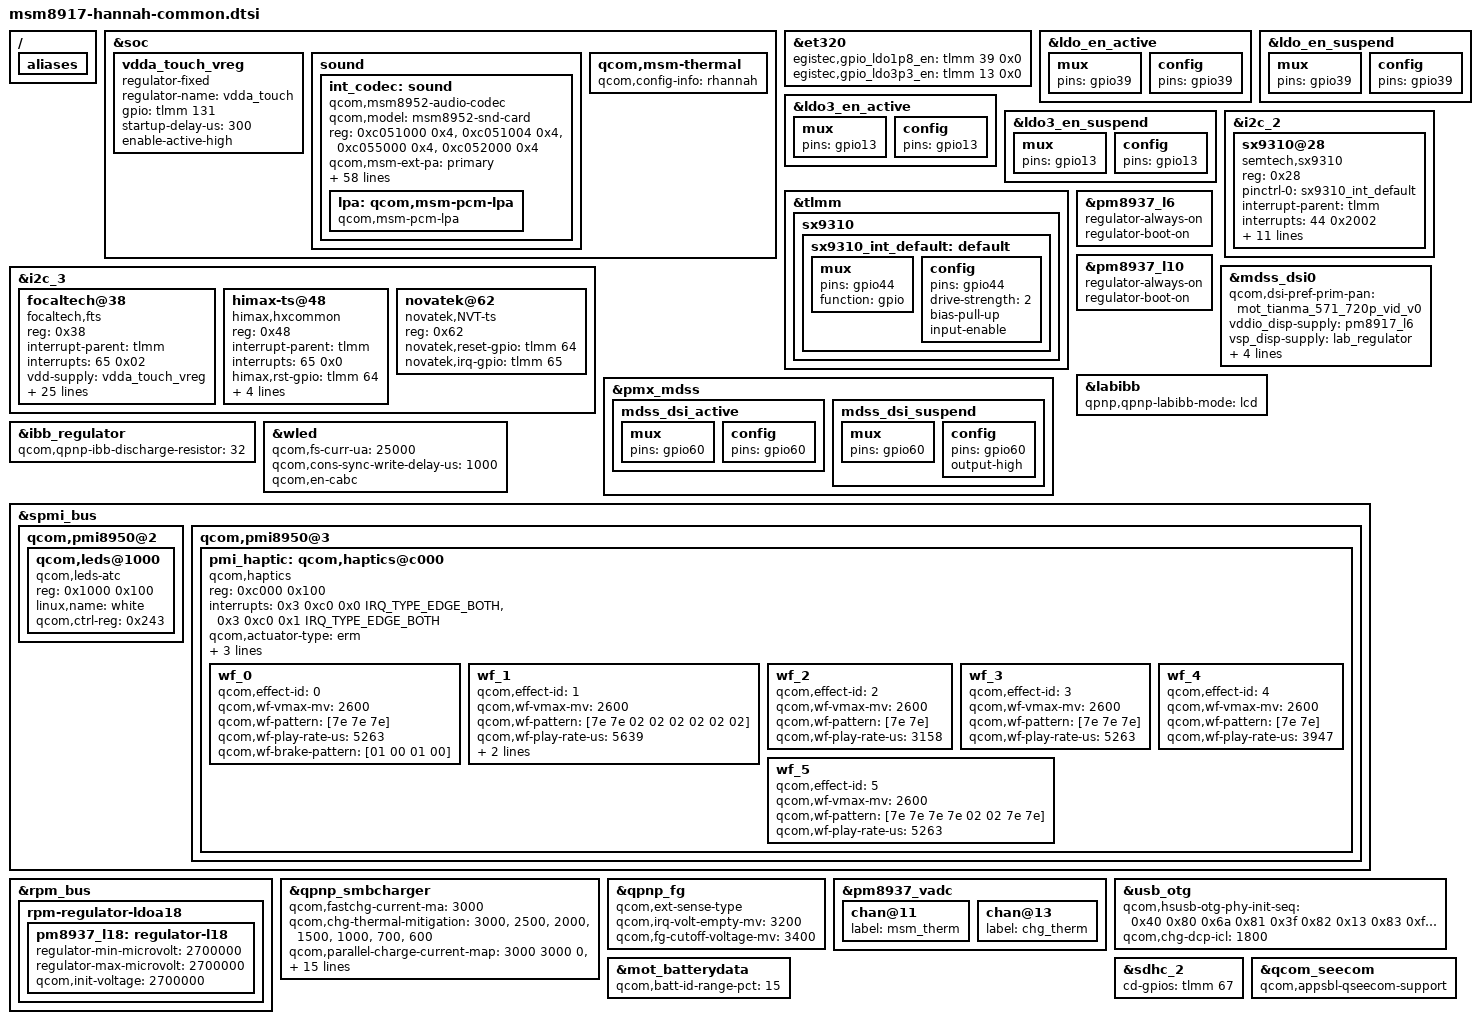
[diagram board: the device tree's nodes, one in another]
/* Copyright (c) 2016, Motorola Mobility Inc. All rights reserved.
 *
 * This program is free software; you can redistribute it and/or modify
 * it under the terms of the GNU General Public License version 2 and
 * only version 2 as published by the Free Software Foundation.
 *
 * This program is distributed in the hope that it will be useful,
 * but WITHOUT ANY WARRANTY; without even the implied warranty of
 * MERCHANTABILITY or FITNESS FOR A PARTICULAR PURPOSE.  See the
 * GNU General Public License for more details.
 */
#include "dsi-panel-mot-tianma-571-720p-video.dtsi"
#include "dsi-panel-mot-djn-599-hd-video.dtsi"
#include "dsi-panel-mot-tianma-599-hd-video.dtsi"
#include "dsi-panel-mot-djn-600-hd-video.dtsi"
#include "msm8917-moto-common-fps.dtsi"

/ {
	aliases {
		/delete-property/ i2c4;
	};
};

&soc {
	/delete-node/ i2c@78b8000;

	vdda_touch_vreg: vdda_touch_vreg {
		compatible = "regulator-fixed";
		regulator-name = "vdda_touch";
		gpio = <&tlmm 131 0>;
		startup-delay-us = <300>;
		enable-active-high;
	};

	sound {
		int_codec: sound {
		    status = "okay";
		    compatible = "qcom,msm8952-audio-codec";
		    qcom,model = "msm8952-snd-card";
		    reg = <0xc051000 0x4>,
		      <0xc051004 0x4>,
		      <0xc055000 0x4>,
		      <0xc052000 0x4>;
		    reg-names = "csr_gp_io_mux_mic_ctl",
		      "csr_gp_io_mux_spkr_ctl",
		      "csr_gp_io_lpaif_pri_pcm_pri_mode_muxsel",
		      "csr_gp_io_mux_quin_ctl";

		    qcom,msm-ext-pa = "primary";
		    qcom,msm-mclk-freq = <9600000>;
		    qcom,msm-mbhc-hphl-swh = <1>;
		    qcom,msm-mbhc-gnd-swh = <1>;
		    qcom,msm-hs-micbias-type = "external";
		    qcom,msm-hs-insert-debounce = <9>;
		    /delete-property/ qcom,msm-micbias2-ext-cap;
		    qcom,msm-micbias1-ext-cap;

		    qcom,audio-routing =
		      "RX_BIAS", "MCLK",
		      "INT_LDO_H", "MCLK",
		      "MIC BIAS External", "Handset Mic",
		      "MIC BIAS External2", "Headset Mic",
		      "MIC BIAS External", "Secondary Mic",
		      "AMIC1", "MIC BIAS External",
		      "AMIC2", "MIC BIAS External2",
		      "AMIC3", "MIC BIAS External";

		    qcom,cdc-us-eu-gpios = <&cdc_us_euro_sw>;
		    qcom,pri-mi2s-gpios = <&cdc_pri_mi2s_gpios>;
		    qcom,quin-mi2s-gpios = <&cdc_quin_mi2s_gpios>;

		    asoc-platform = <&pcm0>, <&pcm1>, <&pcm2>, <&voip>, <&voice>,
		        <&loopback>, <&compress>, <&hostless>,
		        <&afe>, <&lsm>, <&routing>, <&pcm_noirq>;
		    asoc-platform-names = "msm-pcm-dsp.0", "msm-pcm-dsp.1",
		        "msm-pcm-dsp.2", "msm-voip-dsp",
		        "msm-pcm-voice", "msm-pcm-loopback",
		        "msm-compress-dsp", "msm-pcm-hostless",
		        "msm-pcm-afe", "msm-lsm-client",
		        "msm-pcm-routing", "msm-pcm-dsp-noirq";
		    asoc-cpu = <&dai_pri_auxpcm>,
		      <&dai_mi2s0>, <&dai_mi2s1>,
		      <&dai_mi2s2>, <&dai_mi2s3>,
		      <&dai_mi2s4>, <&dai_mi2s5>,
		      <&sb_0_rx>, <&sb_0_tx>, <&sb_1_rx>, <&sb_1_tx>,
		      <&sb_3_rx>, <&sb_3_tx>, <&sb_4_rx>, <&sb_4_tx>,
		      <&bt_sco_rx>, <&bt_sco_tx>,
		      <&int_fm_rx>, <&int_fm_tx>,
		      <&afe_pcm_rx>, <&afe_pcm_tx>,
		      <&afe_proxy_rx>, <&afe_proxy_tx>,
		      <&incall_record_rx>, <&incall_record_tx>,
		      <&incall_music_rx>, <&incall_music_2_rx>,
		      <&proxy_rx>, <&proxy_tx>;

		    asoc-cpu-names = "msm-dai-q6-auxpcm.1",
		        "msm-dai-q6-mi2s.0", "msm-dai-q6-mi2s.1",
		        "msm-dai-q6-mi2s.2", "msm-dai-q6-mi2s.3",
		        "msm-dai-q6-mi2s.4", "msm-dai-q6-mi2s.6",
		        "msm-dai-q6-dev.16384", "msmdai-q6-dev.16385",
		        "msm-dai-q6-dev.16386", "msm-dai-q6-dev.16387",
		        "msm-dai-q6-dev.16390", "msm-dai-q6-dev.16391",
		        "msm-dai-q6-dev.16392", "msm-dai-q6-dev.16393",
		        "msm-dai-q6-dev.12288", "msm-dai-q6-dev.12289",
		        "msm-dai-q6-dev.12292", "msm-dai-q6-dev.12293",
		        "msm-dai-q6-dev.224", "msm-dai-q6-dev.225",
		        "msm-dai-q6-dev.241", "msm-dai-q6-dev.240",
		        "msm-dai-q6-dev.32771", "msm-dai-q6-dev.32772",
		        "msm-dai-q6-dev.32773", "msm-dai-q6-dev.32770",
		        "msm-dai-q6-dev.8194", "msm-dai-q6-dev.8195";

		    asoc-codec = <&stub_codec>, <&msm_digital_codec>,
		        <&pmic_analog_codec>;
		    asoc-codec-names = "msm-stub-codec.1", "msm-dig-codec",
		          "analog-codec";
    
		    qcom,msm-gpios =
		      "pri_i2s";
		    qcom,pinctrl-names =
		      "all_off",
		      "pri_i2s_act";
		    pinctrl-names =
		      "all_off",
		      "pri_i2s_act";
		    pinctrl-0 = <&cdc_pdm_lines_sus &cdc_pdm_lines_2_sus>;
		    pinctrl-1 = <&cdc_pdm_lines_act &cdc_pdm_lines_2_act>;
		    /delete-property/ pinctrl-2;
		    /delete-property/ pinctrl-3;
		    /delete-property/ pinctrl-4;
		    /delete-property/ pinctrl-5;
		    /delete-property/ pinctrl-6;
		    /delete-property/ pinctrl-7;
		    /delete-property/ asoc-wsa-codec-names;
		    /delete-property/ asoc-wsa-codec-prefixes;
		    /delete-property/ msm-vdd-wsa-switch-supply;
		    /delete-property/ qcom,msm-vdd-wsa-switch-voltage;
		    /delete-property/ qcom,msm-vdd-wsa-switch-current;
		    /delete-property/ qcom,hdmi-dba-codec-rx;
		    /delete-property/ qcom,cdc-us-euro-gpios;

			  lpa: qcom,msm-pcm-lpa {
			    compatible = "qcom,msm-pcm-lpa";
			  };
		  };
	};

	/delete-node/ fp_id;
};

&et320 {
	egistec,gpio_ldo1p8_en = <&tlmm 39 0x0>;
	egistec,gpio_ldo3p3_en = <&tlmm 13 0x0>;
};

&ldo_en_active {
	mux {
		pins = "gpio39";
	};
	config {
		pins = "gpio39";
	};
};

&ldo_en_suspend {
	mux {
		pins = "gpio39";
	};
	config {
		pins = "gpio39";
	};
};

&ldo3_en_active {
	mux {
		pins = "gpio13";
	};
	config {
		pins = "gpio13";
	};
};

&ldo3_en_suspend {
	mux {
		pins = "gpio13";
	};
	config {
		pins = "gpio13";
	};
};

&tlmm{
	/delete-node/ sx9310;
	sx9310:sx9310 {
		sx9310_int_default: default {
			mux {
				pins = "gpio44";
				function = "gpio";
			};

			config {
				pins = "gpio44";
				drive-strength = <2>;
				bias-pull-up;
				input-enable;
			};
		};
	};
};

&i2c_2 {
	sx9310@28 {
		compatible = "semtech,sx9310";
		reg = <0x28>;
		pinctrl-names = "default";
		pinctrl-0 = <&sx9310_int_default>;
		interrupt-parent = <&tlmm>;
		interrupts = <44 0x2002>;
		cap_vdd-supply = <&pm8917_l10>;
		cap_svdd-supply = <&pm8937_l5>;
		gpios = <&tlmm 44 0x2008>; /* IRQ */
		cap,use_channel = <0x0f>;
		cap,use_channel_top = <0x00>;
		cap,use_channel_bottom = <0x02>;
		cap,raw_data_channel = <0x01>;
		cap,scan_period = <0x02>;
		reg_array_len = <10>;
		reg_array_val = <0x12 0x03 0x13 0x0a 0x14 0x27 0x15 0xc3 0x17 0x4b 0x18 0x49 0x19 0x39 0x21 0x1a 0x22 0x05 0x23 0x20>;
	};

	/delete-node/ adv7533@39;
	/delete-node/ pericom-type-c@1d;
};


&i2c_3 {
	status = "ok";
	/* clock-frequency = <400000>; */
	focaltech@38{
		compatible = "focaltech,fts";
		reg = <0x38>;
		interrupt-parent = <&tlmm>;
		interrupts = <65 0x02>;
		/* vdd-supply = <&pm8917_l17>; */
		vdd-supply = <&vdda_touch_vreg>;
		vcc_i2c-supply = <&pm8917_l6>;
		/* pins used by touchscreen */
		pinctrl-names = "pmx_ts_active","pmx_ts_suspend","pmx_ts_release";
		pinctrl-0 = <&ts_int_active &ts_reset_active>;
		pinctrl-1 = <&ts_int_suspend &ts_reset_suspend>;
		pinctrl-2 = <&ts_release>;
		focaltech,name = "fts_ts";
		focaltech,family-id = <0x08>;
		focaltech,reset-gpio = <&tlmm 64 0x01>;
		focaltech,irq-gpio = <&tlmm 65 0x02>;
		focaltech,display-coords = <0 0 720 1440>;
		focaltech,max-touch-number = <10>;
		focaltech,no-force-update;
		focaltech,i2c-pull-up;
		focaltech,group-id = <1>;
		focaltech,hard-reset-delay-ms = <20>;
		focaltech,soft-reset-delay-ms = <200>;
		focaltech,num-max-touches = <5>;
		focaltech,fw-delay-aa-ms = <30>;
		focaltech,fw-delay-55-ms = <30>;
		focaltech,fw-upgrade-id1 = <0x79>;
		focaltech,fw-upgrade-id2 = <0x08>;
		focaltech,fw-delay-readid-ms = <10>;
		focaltech,fw-delay-era-flsh-ms = <2000>;
		focaltech,fw-auto-cal;
		focaltech,resume-in-workqueue;
		focaltech,ignore-id-check;
	};
	himax-ts@48 {
		compatible = "himax,hxcommon";
		reg = <0x48>;
		status = "ok";
		interrupt-parent = <&tlmm>;
		interrupts = <65 0x0>;
		//vcc_i2c-supply = <&pm8917_l6>;
		/* pins used by touchscreen */
		himax,rst-gpio = <&tlmm 64 0x00>;
		himax,irq-gpio = <&tlmm 65 0x00>;
		himax,display-coords = <0 720 0 1440>;
		himax,panel-coords = <0 720 0 1440>;
		//himax,button-map = <158 102 139>;
		//himax,fw-auto-update;
		/*himax,force-update;*/
		report_type = <1>;
	};
	novatek@62 {
		compatible = "novatek,NVT-ts";
		reg = <0x62>;
		status = "ok";

		novatek,reset-gpio = <&tlmm 64 0x00>;
		novatek,irq-gpio = <&tlmm 65 0x00>;
	};

};

&pmx_mdss {
	mdss_dsi_active {
		mux {
			pins = "gpio60";
		};

		config {
			pins = "gpio60";
		};
	};

	mdss_dsi_suspend {
		mux {
			pins = "gpio60";
		};

		config {
			pins = "gpio60";
			output-high;
		};
	};
};

&pm8937_l6 {
	regulator-always-on;
	regulator-boot-on;
};

&pm8937_l10 {
	regulator-always-on;
	regulator-boot-on;
};

&mdss_dsi0 {
	qcom,dsi-pref-prim-pan = <&mot_tianma_571_720p_vid_v0>;
	vddio_disp-supply = <&pm8917_l6>;
	vsp_disp-supply = <&lab_regulator>;
	vsn_disp-supply = <&ibb_regulator>;

	pinctrl-names = "mdss_default", "mdss_sleep";
	pinctrl-0 = <&mdss_dsi_active>;
	pinctrl-1 = <&mdss_dsi_suspend>;

	qcom,platform-reset-gpio = <&tlmm 60 0>;
};

/* display boost and inverting boost regulators */
&labibb {
	status = "ok";
	qpnp,qpnp-labibb-mode = "lcd";
};

&ibb_regulator {
	qcom,qpnp-ibb-discharge-resistor = <32>;
};

&wled {
	qcom,fs-curr-ua = <25000>;
	qcom,cons-sync-write-delay-us = <1000>;
	qcom,en-cabc;
};

&spmi_bus {
	qcom,pmi8950@2 {
		/delete-node/ qcom,leds@a100;
		qcom,leds@1000 {
			status = "ok";
			reg = <0x1000 0x100>;
			compatible = "qcom,leds-atc";
			linux,name = "white";
			qcom,ctrl-reg = <0x243>;
		};
	};
};

&rpm_bus {
	rpm-regulator-ldoa18 {
		status = "okay";
		pm8937_l18: regulator-l18 {
			regulator-min-microvolt = <2700000>;
			regulator-max-microvolt = <2700000>;
			qcom,init-voltage = <2700000>;
			status = "okay";
		};
	};
};

&qpnp_smbcharger {
	qcom,fastchg-current-ma = <3000>;
	qcom,chg-thermal-mitigation = <3000>, <2500>,<2000>, <1500>, <1000>,
					<700>, <600>;
	/delete-property/ qcom,dc-thermal-mitigation;
	qcom,parallel-charge-current-map = <3000 3000 0>,
					<2500 2500 0>,
					<2000 2000 0>,
					<1500 1500 0>,
					<1000 1000 0>,
					<700 700 0>,
					<600 600 0>;
	qcom,stepchg-voltage-mv = <4200>;
	qcom,stepchg-current-ma = <2000>;
	qcom,stepchg-taper-ma = <1800>;
	qcom,stepchg-iterm-ma = <125>;
	qcom,enable-hvdcp-9v;
	qcom,weak-charger-check-enable;
	qcom,temp-warm-current-ma = <1500>;
	qcom,temp-cool-current-ma = <900>;
	qcom,temp-slightly-cool-current-ma = <900>;
	qcom,slightly-cool-temp-c = <15>;
	qcom,enable-charging-limit;
	qcom,upper-limit-capacity = <75>;
	qcom,lower-limit-capacity = <60>;
};

&qpnp_fg {
	qcom,ext-sense-type; /* External Sense Resistor */
	/delete-property/ qcom,thermal-coefficients;
	qcom,irq-volt-empty-mv = <3200>;
	qcom,fg-cutoff-voltage-mv = <3400>;
};

&pm8937_vadc {
	chan@11 {
		label = "msm_therm";
	};

	chan@13 {
		label = "chg_therm";
	};
};

&usb_otg {
	qcom,hsusb-otg-phy-init-seq =
		<0x40 0x80 0x6a 0x81 0x3f 0x82 0x13 0x83 0xffffffff>;
	qcom,chg-dcp-icl = <1800>;
};
&soc{
	qcom,msm-thermal {
		qcom,config-info = "rhannah";
	};
};

&mot_batterydata {
	qcom,batt-id-range-pct = <15>;
	#include "batterydata-he50-atl-pmi8937.dtsi"
	#include "batterydata-he50-cos-pmi8937.dtsi"
	#include "batterydata-he50-cos-pmi8937-r1.dtsi"
};

&spmi_bus {
	qcom,pmi8950@3 {
		/delete-node/ qcom,haptics@c000;
		pmi_haptic: qcom,haptics@c000 {
			compatible = "qcom,haptics";
			reg = <0xc000 0x100>;
			interrupts = <0x3 0xc0 0x0 IRQ_TYPE_EDGE_BOTH>,
				     <0x3 0xc0 0x1 IRQ_TYPE_EDGE_BOTH>;
			interrupt-names = "hap-sc-irq", "hap-play-irq";
			qcom,actuator-type = "erm";
			qcom,vmax-mv = <2600>;
			qcom,play-rate-us = <5263>;
			vdd-supply = <&pon_perph_reg>;

			wf_0 {
				/* CLICK */
				qcom,effect-id = <0>;
				qcom,wf-vmax-mv = <2600>;
				qcom,wf-pattern = [7e 7e 7e];
				qcom,wf-play-rate-us = <5263>;
				qcom,wf-brake-pattern = [01 00 01 00];
			};
			wf_1 {
				/* DOUBLE CLICK */
				qcom,effect-id = <1>;
				qcom,wf-vmax-mv = <2600>;
				qcom,wf-pattern = [7e 7e 02 02 02 02 02 02];
				qcom,wf-play-rate-us = <5639>;
				qcom,wf-repeat-count = <2>;
				qcom,wf-s-repeat-count = <1>;
			};
			wf_2 {
				/* TICK */
				qcom,effect-id = <2>;
				qcom,wf-vmax-mv = <2600>;
				qcom,wf-pattern = [7e 7e];
				qcom,wf-play-rate-us = <3158>;
			};
			wf_3 {
				/* THUD */
				qcom,effect-id = <3>;
				qcom,wf-vmax-mv = <2600>;
				qcom,wf-pattern = [7e 7e 7e];
				qcom,wf-play-rate-us = <5263>;
			};
			wf_4 {
				/* POP */
				qcom,effect-id = <4>;
				qcom,wf-vmax-mv = <2600>;
				qcom,wf-pattern = [7e 7e];
				qcom,wf-play-rate-us = <3947>;
			};
			wf_5 {
				/* HEAVY CLICK */
				qcom,effect-id = <5>;
				qcom,wf-vmax-mv = <2600>;
				qcom,wf-pattern = [7e 7e 7e 7e 02 02 7e 7e];
				qcom,wf-play-rate-us = <5263>;
			};
		};
	};
};

&sdhc_2 {
	cd-gpios = <&tlmm 67 0x0>;
};

&qcom_seecom {
	/delete-property/ qcom,commonlib64-loaded-by-uefi;
	qcom,appsbl-qseecom-support;

};

